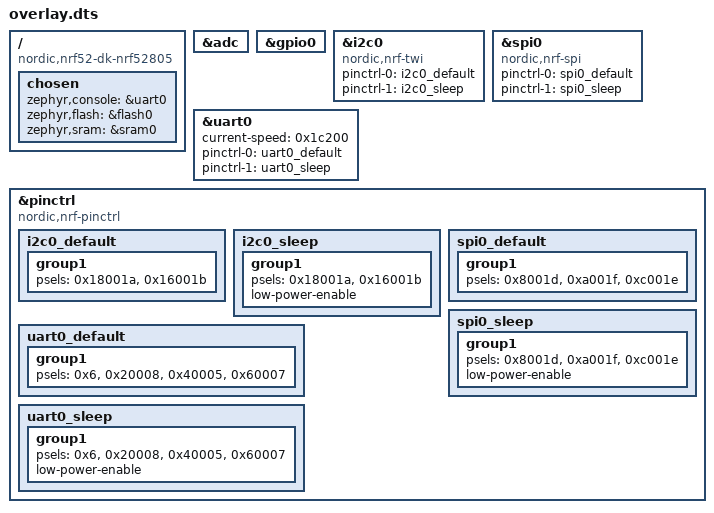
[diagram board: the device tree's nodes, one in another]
/ {
	compatible = "nordic,nrf52-dk-nrf52805";
	chosen {
		zephyr,console = &uart0;
		zephyr,flash = &flash0;
		zephyr,sram = &sram0;
	};
};
&adc{
	status = "okay";
};
&gpio0{
	status = "okay";
};
&i2c0{
	compatible = "nordic,nrf-twi";
	status = "okay";
	pinctrl-0 = < &i2c0_default >;
	pinctrl-1 = < &i2c0_sleep >;
	pinctrl-names = "default", "sleep";
};
&spi0{
	compatible = "nordic,nrf-spi";
	status = "okay";
	pinctrl-0 = < &spi0_default >;
	pinctrl-1 = < &spi0_sleep >;
	pinctrl-names = "default", "sleep";
};
&uart0{
	status = "okay";
	current-speed = < 0x1c200 >;
	pinctrl-0 = < &uart0_default >;
	pinctrl-1 = < &uart0_sleep >;
	pinctrl-names = "default", "sleep";
};
&pinctrl{
	compatible = "nordic,nrf-pinctrl";
	i2c0_default: i2c0_default {
		group1 {
			psels = < 0x18001a >, < 0x16001b >;
		};
	};
	i2c0_sleep: i2c0_sleep {
		group1 {
			psels = < 0x18001a >, < 0x16001b >;
			low-power-enable;
		};
	};
	spi0_default: spi0_default {
		group1 {
			psels = < 0x8001d >, < 0xa001f >, < 0xc001e >;
		};
	};
	spi0_sleep: spi0_sleep {
		group1 {
			psels = < 0x8001d >, < 0xa001f >, < 0xc001e >;
			low-power-enable;
		};
	};
	uart0_default: uart0_default {
		group1 {
			psels = < 0x6 >, < 0x20008 >, < 0x40005 >, < 0x60007 >;
		};
	};
	uart0_sleep: uart0_sleep {
		group1 {
			psels = < 0x6 >, < 0x20008 >, < 0x40005 >, < 0x60007 >;
			low-power-enable;
		};
	};
};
